# cxd5602 register map
Vendor: Sony Semiconductor Solutions; Series: CXD56xx; File version: 1.0
CPU: CM4 r0p1, little endian, MPU, FPU, 3 interrupt priority bits, 144 interrupts
Registers are 32-bit, read-write, reset 0x0 unless marked. A register's access mark holds for its fields unless they carry their own. Offsets are from the block's base; [hi:lo] are bit positions; {n}, {i} and the like mark numbered series; 'fields as' and 'values as' point back to an identical list.

## SPI0 — Synchronous Serial Port Controller (SPIM)
Base 0x041AA000
Same registers: SPI3 0x0418D000
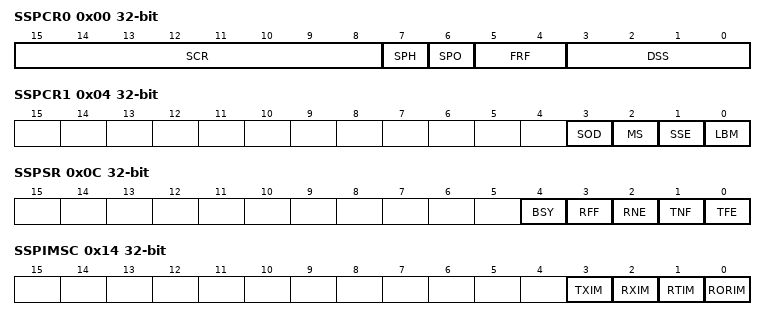
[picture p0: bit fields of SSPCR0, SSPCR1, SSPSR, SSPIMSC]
0x00 SSPCR0 — Control register 0
  [15:8] SCR — Serial clock rate
  [7] SPH — SSPCLKOUT phase
  [6] SPO — SSPCLKOUT polarity
  [5:4] FRF — Frame format
    0=Motorola SPI frame format; 1=TI (TI synchronous serial frame format); 2=NM (National Microwire frame format)
  [3:0] DSS — Data Size Select
    {v}={v+1}bit data (v=3..15)
0x04 SSPCR1 — Control register 1
  [3] SOD — Slave-mode output disable
    0=enable (SSP can drive the SSPTXD output in slave mode); 1=disable (SSP must not drive the SSPTXD output in slave mode)
  [2] MS — Master or slave mode select
    0=Master mode; 1=Slave mode
  [1] SSE — Synchronous serial port enable
    0=disabled (SSP operation disabled); 1=enabled (SSP operation enabled)
  [0] LBM — Loop back mode
    0=disabled (Normal serial port operation enabled); 1=enabled (Output of transmit serial shifter is connected to input of recieve serial shifter internally)
0x08 SSPDR — Data register
  [15:0] DATA read-modifies — Transmit/Receive FIFO
0x0C SSPSR ro — Status register
  [4] BSY — SSP busy flag
    0=idle (SSP is idle); 1=busy (SSP is currently transmitting and/or receiving a frame or the transmit FIFO is not empty)
  [3] RFF — Receive FIFO full
    0=notfull (Receive FIFO is not full); 1=full (Recieve FIFO is full)
  [2] RNE — Rceive FIFIO not empty
    0=empty (Receive FIFO is empty); 1=notempty (Receive FIFO is not empty)
  [1] TNF — Transmit FIFO not full
    0=full (Transmit FIFO is full); 1=notfull (Transmit FIFO is not full)
  [0] TFE — Transmit FIFO empty
    0=notempty (Transmit FIFO is not empty); 1=empty (Transmit FIFO is empty)
0x10 SSPCPSR — Clock prescale register
  [7:0] CPSDVSR — Clock prescale divisor
0x14 SSPIMSC — Interrupt mask set or clear register
  [all] fields
    0=masked; 1=notmasked
  [3] TXIM — Transmit FIFO interrupt mask
  [2] RXIM — Receive FIFO interrupt mask
  [1] RTIM — Receive timeout interrupt mask
  [0] RORIM — Receive overrun interrupt mask
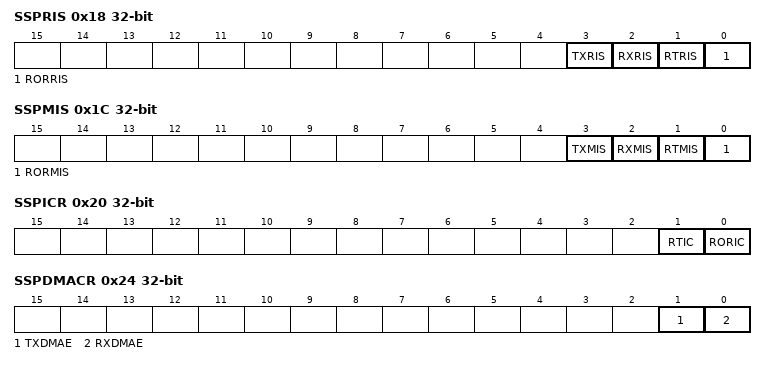
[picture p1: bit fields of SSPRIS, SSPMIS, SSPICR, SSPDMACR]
0x18 SSPRIS ro — Raw interrupt status register
  [all] fields
    0=masked; 1=notmasked
  [3] TXRIS — Transmit FIFO interrupt mask
  [2] RXRIS — Receive FIFO interrupt mask
  [1] RTRIS — Receive timeout interrupt mask
  [0] RORRIS — Receive overrun interrupt mask
0x1C SSPMIS ro — Masked interrupt status register
  [all] fields
    0=masked; 1=notmasked
  [3] TXMIS — Transmit FIFO interrupt mask
  [2] RXMIS — Receive FIFO interrupt mask
  [1] RTMIS — Receive timeout interrupt mask
  [0] RORMIS — Receive overrun interrupt mask
0x20 SSPICR wo — Interrupt clear register
  [1] RTIC — Clear the SSPRTINTR interrupt
  [0] RORIC — Clear the SSPRORINTR interrupt
0x24 SSPDMACR — DMA control register
  [1] TXDMAE — Transmit DMA enable
    0=disabled; 1=enabled
  [0] RXDMAE — Receive DMA enable
    0=disabled; 1=enabled
0x90 CSMODE
  [0] CS_MODE
    0=auto (CS controled by controller); 1=manual (CS controled by CS register)
0x94 SSPCS
  [0] SSP_CS
    0=low (Output low to the CS); 1=high (Output high to the CS)
0x98 SLAVETYPE
  [1:0] SLAVE_TYPE
    0=CS0 (Select CS0); 1=CS1 (Select CS1); 2=CS2 (Select CS2)

## SPI4 — Synchronous Serial Port Controller (IMG SPI)
Base 0x02103400
Same registers: SPI5 0x02103C00
Registers as SPI0, without CSMODE, SSPCS, SLAVETYPE.

## CISIF — CMOS Image Sensor IF
Base 0x02100000
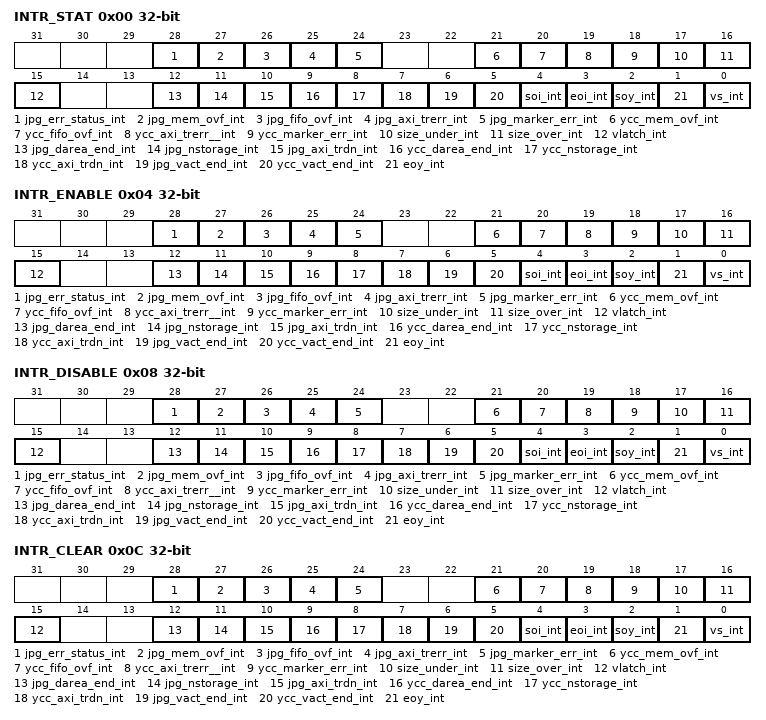
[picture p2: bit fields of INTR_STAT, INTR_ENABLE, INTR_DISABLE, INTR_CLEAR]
0x00 INTR_STAT ro — Interrupt status register
  [28] jpg_err_status_int, [27] jpg_mem_ovf_int, [26] jpg_fifo_ovf_int, [25] jpg_axi_trerr_int, [24] jpg_marker_err_int, [21] ycc_mem_ovf_int, [20] ycc_fifo_ovf_int, [19] ycc_axi_trerr__int, [18] ycc_marker_err_int, [17] size_under_int, [16] size_over_int, [15] vlatch_int, [12] jpg_darea_end_int, [11] jpg_nstorage_int, [10] jpg_axi_trdn_int, [9] ycc_darea_end_int, [8] ycc_nstorage_int, [7] ycc_axi_trdn_int, [6] jpg_vact_end_int, [5] ycc_vact_end_int, [4] soi_int, [3] eoi_int, [2] soy_int, [1] eoy_int, [0] vs_int
0x04 INTR_ENABLE — Interrupt enable register
  fields as INTR_STAT
0x08 INTR_DISABLE wo — Interrupt disable register
  fields as INTR_STAT
0x0C INTR_CLEAR wo — Interrupt clear register
  fields as INTR_STAT
0x20 DIN_ENABLE — Input data enable register
  [0] ycin_enable
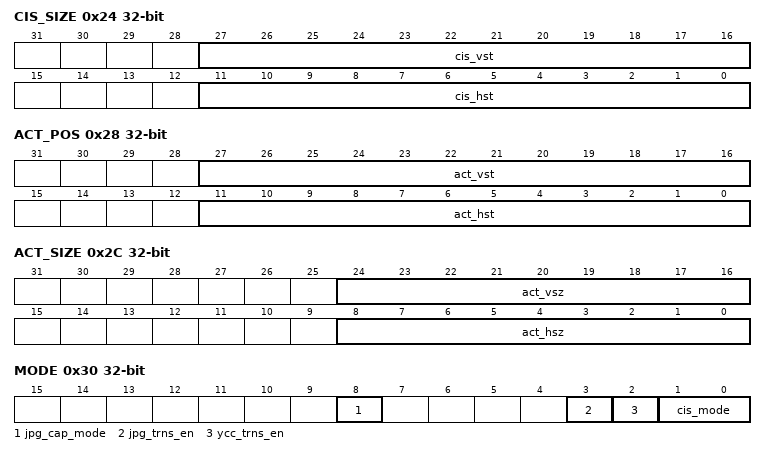
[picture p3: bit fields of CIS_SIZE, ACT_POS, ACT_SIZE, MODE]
0x24 CIS_SIZE — CIS input activa area size setting register
  [27:16] cis_vst, [11:0] cis_hst
0x28 ACT_POS — Active area position setting register
  [27:16] act_vst, [11:0] act_hst
0x2C ACT_SIZE — Active area size setting register
  [24:16] act_vsz, [8:0] act_hsz
0x30 MODE — CIS input mode register
  [8] jpg_cap_mode, [3] jpg_trns_en, [2] ycc_trns_en, [1:0] cis_mode
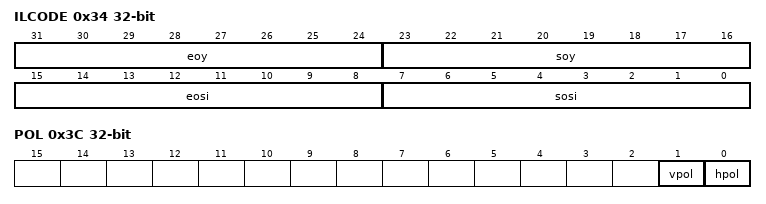
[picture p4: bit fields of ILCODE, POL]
0x34 ILCODE — CIS input in line code setting register
  [31:24] eoy, [23:16] soy, [15:8] eosi, [7:0] sosi
0x38 FORMAT — CIS input data format setting register
  [1:0] yc_order
    0=YCbYCr; 1=YCrYCb; 2=CbYCrY; 3=CrYCbY
0x3C POL — CIS input Vsync/Hsync polarity setting register
  [1] vpol
    0=lowactive (Vsync low active); 1=highactive (Vsync high active)
  [0] hpol
    0=lowactive (Hsync low active); 1=highactive (Hsync high active)
0x40 YCC_START_ADDR — YCC data frame memory start address
0x44 YCC_DAREA_SIZE — YCC data frame memory area size
0x48 YCC_NSTRG_SIZE — YCC data frame memory notice of storage size
0x4C YCC_DSTRG_CONT 16-bit ro — YCC data frame memory storage size counter
0x50 YCC_DREAD_CONT — YCC data frame memory read counter
0x60 JPG_START_ADDR — JPEG data frame memory start address
0x64 JPG_DAREA_SIZE — JPEG data frame memory area size
0x68 JPG_NSTRG_SIZE — JPEG data frame memory notice of storage size
0x6C JPG_DSTRG_CONT 16-bit ro — JPEG data frame memory storage size counter
0x70 JPG_DREAD_CONT — JPEG data frame memory read counter
0x80 EXE_CMD wo — Execution command register
  [0] exe_cmd
